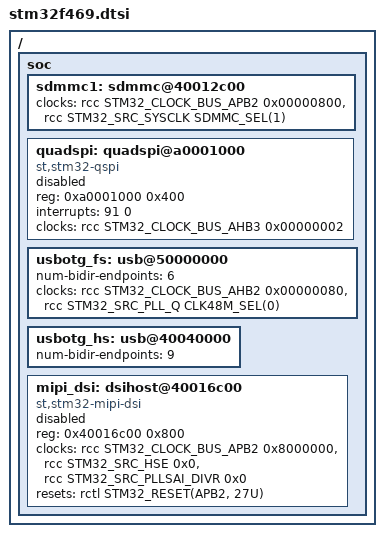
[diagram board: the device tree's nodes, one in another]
/*
 * Copyright (c) 2017 Linaro Limited
 *
 * SPDX-License-Identifier: Apache-2.0
 */

#include <st/f4/stm32f429.dtsi>
#include <zephyr/dt-bindings/mipi_dsi/mipi_dsi.h>

/ {
	soc {
		sdmmc1: sdmmc@40012c00 {
			clocks = <&rcc STM32_CLOCK_BUS_APB2 0x00000800>,
				 <&rcc STM32_SRC_SYSCLK SDMMC_SEL(1)>;
		};

		quadspi: quadspi@a0001000 {
			compatible = "st,stm32-qspi";
			#address-cells = <0x1>;
			#size-cells = <0x0>;
			reg = <0xa0001000 0x400>;
			interrupts = <91 0>;
			clocks = <&rcc STM32_CLOCK_BUS_AHB3 0x00000002>;
			status = "disabled";
		};

		usbotg_fs: usb@50000000 {
			num-bidir-endpoints = <6>;
			clocks = <&rcc STM32_CLOCK_BUS_AHB2 0x00000080>,
				 <&rcc STM32_SRC_PLL_Q CLK48M_SEL(0)>;
		};

		usbotg_hs: usb@40040000 {
			num-bidir-endpoints = <9>;
		};

		mipi_dsi: dsihost@40016c00 {
			compatible = "st,stm32-mipi-dsi";
			#address-cells = <1>;
			#size-cells = <0>;
			reg = <0x40016c00 0x800>;
			// dsiclk - DSI register clock (APB2)
			// refclk - DSI PLL input clock (HSE)
			// pixelclk - LCD-TFT clock (PLLSAI_R)
			// DSI Clock Mux is not used - driver always configures to use PHY DSI clock 
			clock-names = "dsiclk", "refclk", "pixelclk";
			clocks = <&rcc STM32_CLOCK_BUS_APB2 0x8000000>,
				 <&rcc STM32_SRC_HSE 0x0>,	// 0x0 - whatever
				 <&rcc STM32_SRC_PLLSAI_DIVR 0x0>;		// 0x0 whatever - not used
			resets = <&rctl STM32_RESET(APB2, 27U)>;
			status = "disabled";
		};
	};
};
